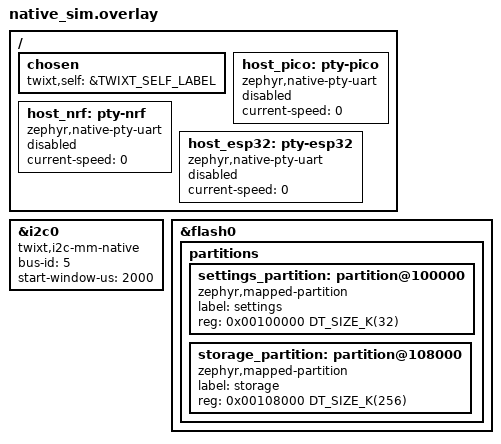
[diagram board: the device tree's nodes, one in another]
/*
 * Copyright (c) 2026 Christoph Jans <jans.christoph@gmail.com>
 *
 * SPDX-License-Identifier: Apache-2.0
 */

/* The bus on native_sim (twixt,i2c-mm-native); TWIXT_SELF_LABEL is mcu_<MCU> */

/ {
	chosen {
		twixt,self = &TWIXT_SELF_LABEL;
	};

	/* The gateway's ports to the laptop (gw-native.overlay enables them):
	 * "pty-pico connected to pseudotty: /dev/pts/N"
	 */
	host_pico: pty-pico {
		compatible = "zephyr,native-pty-uart";
		current-speed = <0>;
		status = "disabled";
	};

	host_nrf: pty-nrf {
		compatible = "zephyr,native-pty-uart";
		current-speed = <0>;
		status = "disabled";
	};

	host_esp32: pty-esp32 {
		compatible = "zephyr,native-pty-uart";
		current-speed = <0>;
		status = "disabled";
	};
};

&i2c0 {
	compatible = "twixt,i2c-mm-native";
	bus-id = <5>;
	start-window-us = <2000>;

#include "../twixt_mcus.dtsi"
};

/* A board's partitions, after the stock ones, which end at 1 MiB; the stock
 * storage_partition goes, so that there is one storage
 */
/delete-node/ &storage_partition;

&flash0 {
	partitions {
		settings_partition: partition@100000 {
			compatible = "zephyr,mapped-partition";
			label = "settings";
			reg = <0x00100000 DT_SIZE_K(32)>;
		};

		storage_partition: partition@108000 {
			compatible = "zephyr,mapped-partition";
			label = "storage";
			reg = <0x00108000 DT_SIZE_K(256)>;
		};
	};
};
